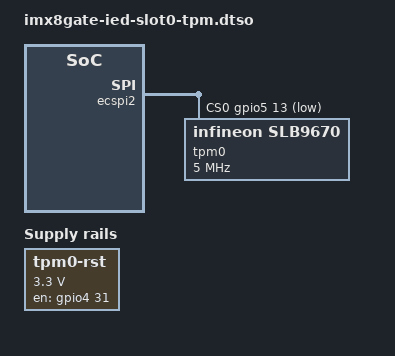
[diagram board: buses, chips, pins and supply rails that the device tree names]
/dts-v1/;
/plugin/;

#include <dt-bindings/gpio/gpio.h>
#include <dt-bindings/interrupt-controller/irq.h>
#include "../freescale/imx8mm-pinfunc.h"

/ {
	fragment@0 {
		target-path = "/";
		__overlay__ {
			regulator-tpm0-rst {
				compatible = "regulator-fixed";
				regulator-name = "tpm0-rst";
				regulator-min-microvolt = <3300000>;
				regulator-max-microvolt = <3300000>;
				gpio = <&gpio4 31 GPIO_ACTIVE_HIGH>;
				regulator-always-on;
				enable-active-high;
			};
		};
	};

	fragment@1 {
		target = <&ecspi2>;
		__overlay__ {
			#address-cells = <1>;
			#size-cells = <0>;
			fsl,spi-num-chipselects = <1>;
			pinctrl-names = "default";
			pinctrl-0 = <&pinctrl_ecspi2_sb_iotgimx8_ied &pinctrl_ecspi2_cs_sb_iotgimx8_ied>;
			cs-gpios = <&gpio5 13 GPIO_ACTIVE_LOW>;
			status = "okay";

			tpm0: tpm@0 {
				compatible = "infineon,slb9670", "tcg,tpm_tis-spi";
				reg = <0>;
				pinctrl-names = "default";
				pinctrl-0 = <&pinctrl_tpm0_sb_iotgimx8_ied>;
				spi-max-frequency = <5000000>;
				status = "okay";
			};
		};
	};
};
